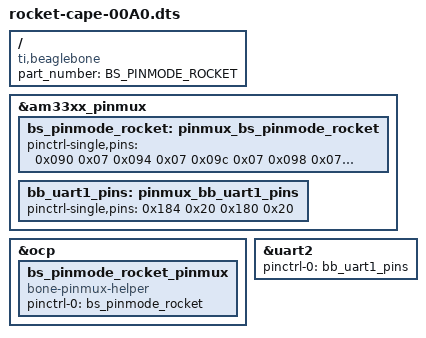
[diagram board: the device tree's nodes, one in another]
/*
 * This is an overlay for the beagle bone black in the launch rail.
 * The purpose is to set up the BBB to use the gpio of P8 for the ARM and IGNITE signal.
 * Author: Patricio Castillo Calderon
 */

/dts-v1/;
/plugin/;

/{
    compatible = "ti,beaglebone", "ti,beaglebone-black";
    part_number = "BS_PINMODE_ROCKET";

    fragment@0 {
        target = <&am33xx_pinmux>;
        __overlay__ {
            bs_pinmode_rocket: pinmux_bs_pinmode_rocket {
                pinctrl-single,pins = <
			0x090 0x07 /* P8_7 */
                        0x094 0x07 /* P8_8 */
                        0x09c 0x07 /* P8_9 */
                        0x098 0x07 /* P8_10 */
                        0x034 0x07 /* P8_11 */
                        0x030 0x07 /* P8_12 */
                        0x024 0x07 /* P8_13 */
                        0x028 0x07 /* P8_14 */
                        0x03c 0x07 /* P8_15 */
                        0x038 0x07 /* P8_16 */
                        0x02c 0x07 /* P8_17 */
                        0x08c 0x07 /* P8_18 */
                >;
            };
        };
    };

    fragment@1 {
        target = <&ocp>;
        __overlay__ {
            bs_pinmode_rocket_pinmux {
                compatible = "bone-pinmux-helper";
                status = "okay";
                pinctrl-names = "default";
                pinctrl-0 = <&bs_pinmode_rocket>;
            };
        };
    };

    fragment@2 {
                target = <&am33xx_pinmux>;
                __overlay__ {
                        bb_uart1_pins: pinmux_bb_uart1_pins {
                                pinctrl-single,pins = <
                                        0x184 0x20 /* P9.24 uart1_txd.uart1_txd MODE0 OUTPUT (TX) */
                                        0x180 0x20 /* P9.26 uart1_rxd.uart1_rxd MODE0 INPUT (RX) */
                                >;
                        };
                };
        };

	fragment@3 {
                target = <&uart2>;	/* really uart1 */
                __overlay__ {
                        status = "okay";
                        pinctrl-names = "default";
                        pinctrl-0 = <&bb_uart1_pins>;
                };
        };
};

